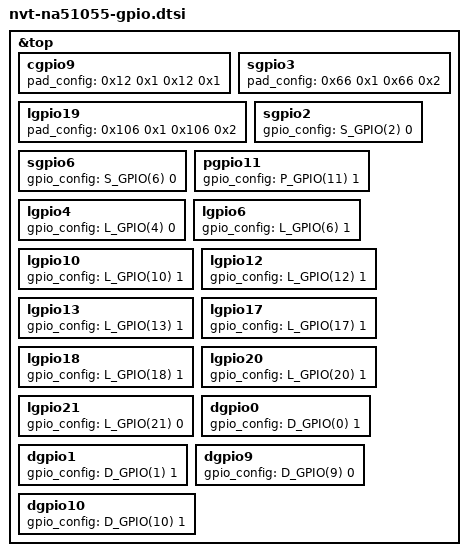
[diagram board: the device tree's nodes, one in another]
&top {
cgpio9{pad_config = <0x12 0x1 0x12 0x1>;}; /* GSENSOR_INT */
sgpio3{pad_config = <0x66 0x1 0x66 0x2>;}; /* ACC_DET */
lgpio19{pad_config = <0x106 0x1 0x106 0x2>;}; /* ETH_DET */
//cgpio4{gpio_config = <C_GPIO(4) 1>;}; /* BT_WAKE */
sgpio2{gpio_config = <S_GPIO(2) 0>;}; /* BL_PCTL Back Light */
sgpio6{gpio_config = <S_GPIO(6) 0>;}; /* SN1_RESET */
pgpio11{gpio_config = <P_GPIO(11) 1>;}; /* TVI_RESET */
lgpio4{gpio_config = <L_GPIO(4) 0>;}; /* Gsen_PWR_OFF */
lgpio6{gpio_config = <L_GPIO(6) 1>;}; /* TVI_PWR_ON */
lgpio10{gpio_config = <L_GPIO(10) 1>;}; /* SN1_11EN */
lgpio12{gpio_config = <L_GPIO(12) 1>;}; /* SN1_18EN */
lgpio13{gpio_config = <L_GPIO(13) 1>;}; /* GPS_PWR_EN */
lgpio17{gpio_config = <L_GPIO(17) 1>;}; /* APAMP_EN */
lgpio18{gpio_config = <L_GPIO(18) 1>;}; /* WIFI_PWR_EN */
lgpio20{gpio_config = <L_GPIO(20) 1>;}; /* ETH_PWR_ON */
lgpio21{gpio_config = <L_GPIO(21) 0>;}; /* LCD_RESET */
dgpio0{gpio_config = <D_GPIO(0) 1>;}; /* WL_REG_ON */
dgpio1{gpio_config = <D_GPIO(1) 1>;}; /* SD_POWER */
dgpio9{gpio_config = <D_GPIO(9) 0>;}; /* BT_RST */
dgpio10{gpio_config = <D_GPIO(10) 1>;}; /* LED_BUSY */
};
